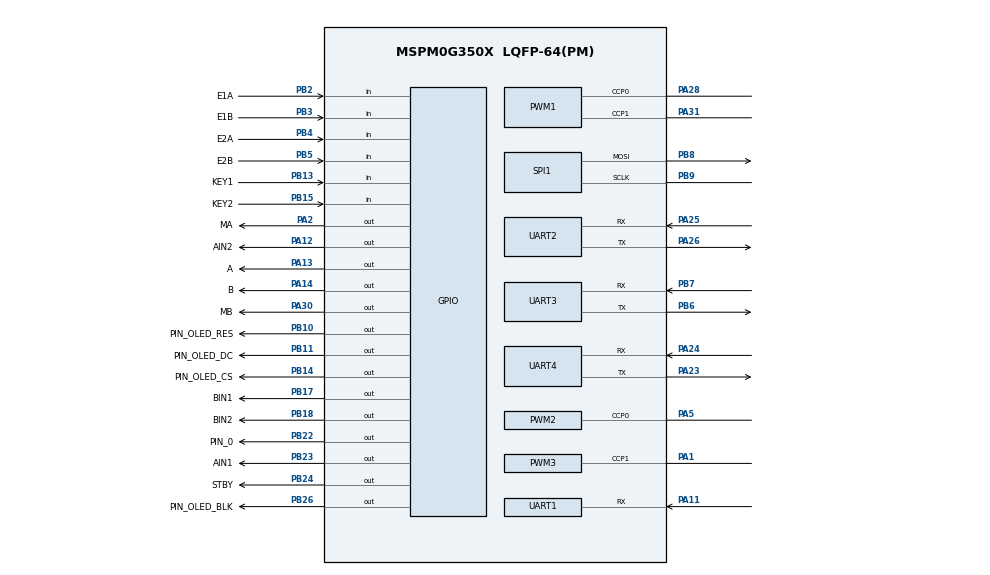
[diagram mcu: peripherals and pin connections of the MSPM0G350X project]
/**
 * @cliArgs --device "MSPM0G350X" --part "Default" --package "LQFP-64(PM)" --product "mspm0_sdk@2.10.00.04"
 * @versions {"tool":"1.26.2+4477"}
 */

/**
 * Import the modules used in this configuration.
 */
const GPIO   = scripting.addModule("/ti/driverlib/GPIO", {}, false);
const GPIO1  = GPIO.addInstance();
const GPIO2  = GPIO.addInstance();
const GPIO3  = GPIO.addInstance();
const GPIO4  = GPIO.addInstance();
const GPIO5  = GPIO.addInstance();
const GPIO6  = GPIO.addInstance();
const GPIO7  = GPIO.addInstance();
const GPIO8  = GPIO.addInstance();
const I2C    = scripting.addModule("/ti/driverlib/I2C", {}, false);
const I2C1   = I2C.addInstance();
const PWM    = scripting.addModule("/ti/driverlib/PWM", {}, false);
const PWM1   = PWM.addInstance();
const PWM2   = PWM.addInstance();
const PWM3   = PWM.addInstance();
const SPI    = scripting.addModule("/ti/driverlib/SPI", {}, false);
const SPI1   = SPI.addInstance();
const SYSCTL = scripting.addModule("/ti/driverlib/SYSCTL");
const TIMER  = scripting.addModule("/ti/driverlib/TIMER", {}, false);
const TIMER1 = TIMER.addInstance();
const UART   = scripting.addModule("/ti/driverlib/UART", {}, false);
const UART1  = UART.addInstance();
const UART2  = UART.addInstance();
const UART3  = UART.addInstance();
const UART4  = UART.addInstance();

/**
 * Write custom configuration values to the imported modules.
 */
const divider7       = system.clockTree["PLL_PDIV"];
divider7.divideValue = 2;

const divider9       = system.clockTree["UDIV"];
divider9.divideValue = 2;

const multiplier2         = system.clockTree["PLL_QDIV"];
multiplier2.multiplyValue = 5;

const mux8       = system.clockTree["HSCLKMUX"];
mux8.inputSelect = "HSCLKMUX_SYSPLL2X";

const pinFunction4       = system.clockTree["HFXT"];
pinFunction4.HFXTStartup = 10;

GPIO1.$name                         = "DC_MOTOR";
GPIO1.associatedPins.create(5);
GPIO1.associatedPins[0].$name       = "STBY";
GPIO1.associatedPins[0].pin.$assign = "PB24";
GPIO1.associatedPins[1].$name       = "AIN1";
GPIO1.associatedPins[1].pin.$assign = "PB23";
GPIO1.associatedPins[2].$name       = "AIN2";
GPIO1.associatedPins[2].pin.$assign = "PA12";
GPIO1.associatedPins[3].$name       = "BIN1";
GPIO1.associatedPins[3].pin.$assign = "PB17";
GPIO1.associatedPins[4].$name       = "BIN2";
GPIO1.associatedPins[4].pin.$assign = "PB18";

const Board = scripting.addModule("/ti/driverlib/Board", {}, false);

GPIO2.$name                         = "KEY";
GPIO2.associatedPins.create(2);
GPIO2.associatedPins[0].$name       = "KEY2";
GPIO2.associatedPins[0].direction   = "INPUT";
GPIO2.associatedPins[0].interruptEn = true;
GPIO2.associatedPins[0].polarity    = "RISE";
GPIO2.associatedPins[0].pin.$assign = "PB15";
GPIO2.associatedPins[1].$name       = "KEY1";
GPIO2.associatedPins[1].direction   = "INPUT";
GPIO2.associatedPins[1].interruptEn = true;
GPIO2.associatedPins[1].polarity    = "RISE";
GPIO2.associatedPins[1].pin.$assign = "PB13";

GPIO3.$name                               = "ENCODERA";
GPIO3.associatedPins.create(2);
GPIO3.associatedPins[0].$name             = "E1A";
GPIO3.associatedPins[0].direction         = "INPUT";
GPIO3.associatedPins[0].interruptEn       = true;
GPIO3.associatedPins[0].interruptPriority = "0";
GPIO3.associatedPins[0].polarity          = "RISE";
GPIO3.associatedPins[0].pin.$assign       = "PB2";
GPIO3.associatedPins[1].$name             = "E1B";
GPIO3.associatedPins[1].direction         = "INPUT";
GPIO3.associatedPins[1].interruptEn       = true;
GPIO3.associatedPins[1].interruptPriority = "0";
GPIO3.associatedPins[1].polarity          = "RISE";
GPIO3.associatedPins[1].pin.$assign       = "PB3";

GPIO4.$name                               = "ENCODERB";
GPIO4.associatedPins.create(2);
GPIO4.associatedPins[0].$name             = "E2A";
GPIO4.associatedPins[0].direction         = "INPUT";
GPIO4.associatedPins[0].interruptEn       = true;
GPIO4.associatedPins[0].interruptPriority = "0";
GPIO4.associatedPins[0].polarity          = "RISE";
GPIO4.associatedPins[0].pin.$assign       = "PB4";
GPIO4.associatedPins[1].$name             = "E2B";
GPIO4.associatedPins[1].direction         = "INPUT";
GPIO4.associatedPins[1].interruptEn       = true;
GPIO4.associatedPins[1].interruptPriority = "0";
GPIO4.associatedPins[1].polarity          = "RISE";
GPIO4.associatedPins[1].pin.$assign       = "PB5";

GPIO5.$name                              = "LED";
GPIO5.associatedPins[0].$name            = "PIN_0";
GPIO5.associatedPins[0].internalResistor = "PULL_DOWN";
GPIO5.associatedPins[0].pin.$assign      = "PB22";

GPIO6.$name                         = "DIR";
GPIO6.associatedPins.create(2);
GPIO6.associatedPins[0].$name       = "A";
GPIO6.associatedPins[0].pin.$assign = "PA13";
GPIO6.associatedPins[1].$name       = "B";
GPIO6.associatedPins[1].pin.$assign = "PA14";

GPIO7.$name                         = "GPIO_OLED";
GPIO7.associatedPins.create(4);
GPIO7.associatedPins[0].$name       = "PIN_OLED_RES";
GPIO7.associatedPins[0].pin.$assign = "PB10";
GPIO7.associatedPins[1].$name       = "PIN_OLED_DC";
GPIO7.associatedPins[1].pin.$assign = "PB11";
GPIO7.associatedPins[2].$name       = "PIN_OLED_CS";
GPIO7.associatedPins[2].pin.$assign = "PB14";
GPIO7.associatedPins[3].$name       = "PIN_OLED_BLK";
GPIO7.associatedPins[3].pin.$assign = "PB26";

GPIO8.$name                         = "EN";
GPIO8.associatedPins.create(2);
GPIO8.associatedPins[0].$name       = "MA";
GPIO8.associatedPins[0].pin.$assign = "PA2";
GPIO8.associatedPins[1].$name       = "MB";
GPIO8.associatedPins[1].pin.$assign = "PA30";

I2C1.$name                             = "I2C_OLED";
I2C1.basicEnableController             = true;
I2C1.basicControllerStandardBusSpeed   = "Fast";
I2C1.sdaPinConfig.hideOutputInversion  = scripting.forceWrite(false);
I2C1.sdaPinConfig.onlyInternalResistor = scripting.forceWrite(false);
I2C1.sdaPinConfig.passedPeripheralType = scripting.forceWrite("Digital");
I2C1.sdaPinConfig.$name                = "ti_driverlib_gpio_GPIOPinGeneric5";
I2C1.sclPinConfig.hideOutputInversion  = scripting.forceWrite(false);
I2C1.sclPinConfig.onlyInternalResistor = scripting.forceWrite(false);
I2C1.sclPinConfig.passedPeripheralType = scripting.forceWrite("Digital");
I2C1.sclPinConfig.$name                = "ti_driverlib_gpio_GPIOPinGeneric6";

PWM1.$name                              = "PWMAB";
PWM1.clockDivider                       = 2;
PWM1.timerStartTimer                    = true;
PWM1.clockPrescale                      = 20;
PWM1.pwmMode                            = "EDGE_ALIGN_UP";
PWM1.timerCount                         = 100;
PWM1.peripheral.$assign                 = "TIMA1";
PWM1.peripheral.ccp0Pin.$assign         = "PA28";
PWM1.peripheral.ccp1Pin.$assign         = "PA31";
PWM1.PWM_CHANNEL_0.$name                = "ti_driverlib_pwm_PWMTimerCC0";
PWM1.PWM_CHANNEL_1.$name                = "ti_driverlib_pwm_PWMTimerCC1";
PWM1.ccp0PinConfig.direction            = scripting.forceWrite("OUTPUT");
PWM1.ccp0PinConfig.hideOutputInversion  = scripting.forceWrite(false);
PWM1.ccp0PinConfig.onlyInternalResistor = scripting.forceWrite(false);
PWM1.ccp0PinConfig.passedPeripheralType = scripting.forceWrite("Digital");
PWM1.ccp0PinConfig.$name                = "ti_driverlib_gpio_GPIOPinGeneric0";
PWM1.ccp1PinConfig.direction            = scripting.forceWrite("OUTPUT");
PWM1.ccp1PinConfig.hideOutputInversion  = scripting.forceWrite(false);
PWM1.ccp1PinConfig.onlyInternalResistor = scripting.forceWrite(false);
PWM1.ccp1PinConfig.passedPeripheralType = scripting.forceWrite("Digital");
PWM1.ccp1PinConfig.$name                = "ti_driverlib_gpio_GPIOPinGeneric2";

PWM2.$name                              = "PWM_0";
PWM2.timerStartTimer                    = true;
PWM2.ccIndex                            = [0];
PWM2.pwmMode                            = "EDGE_ALIGN_UP";
PWM2.timerCount                         = 1;
PWM2.clockPrescale                      = 4;
PWM2.PWM_CHANNEL_0.$name                = "ti_driverlib_pwm_PWMTimerCC2";
PWM2.ccp0PinConfig.direction            = scripting.forceWrite("OUTPUT");
PWM2.ccp0PinConfig.hideOutputInversion  = scripting.forceWrite(false);
PWM2.ccp0PinConfig.onlyInternalResistor = scripting.forceWrite(false);
PWM2.ccp0PinConfig.passedPeripheralType = scripting.forceWrite("Digital");
PWM2.ccp0PinConfig.$name                = "ti_driverlib_gpio_GPIOPinGeneric13";
PWM2.peripheral.$assign                 = "TIMG0";
PWM2.peripheral.ccp0Pin.$assign         = "PA5";

PWM3.$name                              = "PWM_1";
PWM3.clockPrescale                      = 8;
PWM3.pwmMode                            = "EDGE_ALIGN_UP";
PWM3.ccIndex                            = [1];
PWM3.timerCount                         = 1;
PWM3.timerStartTimer                    = true;
PWM3.ccp1PinConfig.direction            = scripting.forceWrite("OUTPUT");
PWM3.ccp1PinConfig.hideOutputInversion  = scripting.forceWrite(false);
PWM3.ccp1PinConfig.onlyInternalResistor = scripting.forceWrite(false);
PWM3.ccp1PinConfig.passedPeripheralType = scripting.forceWrite("Digital");
PWM3.ccp1PinConfig.$name                = "ti_driverlib_gpio_GPIOPinGeneric16";
PWM3.peripheral.$assign                 = "TIMA0";
PWM3.peripheral.ccp1Pin.$assign         = "PA1";
PWM3.PWM_CHANNEL_1.$name                = "ti_driverlib_pwm_PWMTimerCC3";

SPI1.$name                              = "SPI_OLED";
SPI1.frameFormat                        = "MOTO3";
SPI1.direction                          = "PICO";
SPI1.sclkPinConfig.direction            = scripting.forceWrite("OUTPUT");
SPI1.sclkPinConfig.onlyInternalResistor = scripting.forceWrite(false);
SPI1.sclkPinConfig.passedPeripheralType = scripting.forceWrite("Digital");
SPI1.sclkPinConfig.$name                = "ti_driverlib_gpio_GPIOPinGeneric7";
SPI1.mosiPinConfig.direction            = scripting.forceWrite("OUTPUT");
SPI1.mosiPinConfig.hideOutputInversion  = scripting.forceWrite(false);
SPI1.mosiPinConfig.onlyInternalResistor = scripting.forceWrite(false);
SPI1.mosiPinConfig.passedPeripheralType = scripting.forceWrite("Digital");
SPI1.mosiPinConfig.$name                = "ti_driverlib_gpio_GPIOPinGeneric12";
SPI1.peripheral.$assign                 = "SPI1";
SPI1.peripheral.sclkPin.$assign         = "PB9";
SPI1.peripheral.mosiPin.$assign         = "PB8";

SYSCTL.forceDefaultClkConfig = true;
SYSCTL.clockTreeEn           = true;

TIMER1.$name              = "TIMER_0";
TIMER1.timerStartTimer    = true;
TIMER1.interrupts         = ["ZERO"];
TIMER1.timerMode          = "PERIODIC";
TIMER1.timerClkDiv        = 8;
TIMER1.timerClkPrescale   = 128;
TIMER1.timerPeriod        = "20 ms";
TIMER1.peripheral.$assign = "TIMG7";

UART1.$name                            = "UART_BNO08X";
UART1.targetBaudRate                   = 115200;
UART1.direction                        = "RX";
UART1.enableFIFO                       = true;
UART1.rxTimeoutValue                   = 1;
UART1.enabledInterrupts                = ["RX_TIMEOUT_ERROR"];
UART1.enabledDMARXTriggers             = "DL_UART_DMA_INTERRUPT_RX";
UART1.rxPinConfig.hideOutputInversion  = scripting.forceWrite(false);
UART1.rxPinConfig.onlyInternalResistor = scripting.forceWrite(false);
UART1.rxPinConfig.passedPeripheralType = scripting.forceWrite("Digital");
UART1.rxPinConfig.$name                = "ti_driverlib_gpio_GPIOPinGeneric1";
UART1.peripheral.$assign               = "UART0";
UART1.peripheral.rxPin.$assign         = "PA11";
UART1.DMA_CHANNEL_RX.addressMode       = "f2b";
UART1.DMA_CHANNEL_RX.srcLength         = "BYTE";
UART1.DMA_CHANNEL_RX.dstLength         = "BYTE";
UART1.DMA_CHANNEL_RX.$name             = "DMA_BNO08X";

UART2.$name                            = "UART_DEBUG";
UART2.targetBaudRate                   = 115200;
UART2.enabledInterrupts                = ["RX"];
UART2.peripheral.rxPin.$assign         = "PA25";
UART2.peripheral.txPin.$assign         = "PA26";
UART2.txPinConfig.direction            = scripting.forceWrite("OUTPUT");
UART2.txPinConfig.hideOutputInversion  = scripting.forceWrite(false);
UART2.txPinConfig.onlyInternalResistor = scripting.forceWrite(false);
UART2.txPinConfig.passedPeripheralType = scripting.forceWrite("Digital");
UART2.txPinConfig.$name                = "ti_driverlib_gpio_GPIOPinGeneric3";
UART2.rxPinConfig.hideOutputInversion  = scripting.forceWrite(false);
UART2.rxPinConfig.onlyInternalResistor = scripting.forceWrite(false);
UART2.rxPinConfig.passedPeripheralType = scripting.forceWrite("Digital");
UART2.rxPinConfig.$name                = "ti_driverlib_gpio_GPIOPinGeneric4";

UART3.$name                            = "UART_STEPMOTOR1";
UART3.targetBaudRate                   = 115200;
UART3.peripheral.rxPin.$assign         = "PB7";
UART3.peripheral.txPin.$assign         = "PB6";
UART3.txPinConfig.direction            = scripting.forceWrite("OUTPUT");
UART3.txPinConfig.hideOutputInversion  = scripting.forceWrite(false);
UART3.txPinConfig.onlyInternalResistor = scripting.forceWrite(false);
UART3.txPinConfig.passedPeripheralType = scripting.forceWrite("Digital");
UART3.txPinConfig.$name                = "ti_driverlib_gpio_GPIOPinGeneric8";
UART3.rxPinConfig.hideOutputInversion  = scripting.forceWrite(false);
UART3.rxPinConfig.onlyInternalResistor = scripting.forceWrite(false);
UART3.rxPinConfig.passedPeripheralType = scripting.forceWrite("Digital");
UART3.rxPinConfig.$name                = "ti_driverlib_gpio_GPIOPinGeneric9";

UART4.$name                            = "UART_STEPMOTOR2";
UART4.targetBaudRate                   = 115200;
UART4.peripheral.$assign               = "UART2";
UART4.peripheral.rxPin.$assign         = "PA24";
UART4.peripheral.txPin.$assign         = "PA23";
UART4.txPinConfig.direction            = scripting.forceWrite("OUTPUT");
UART4.txPinConfig.hideOutputInversion  = scripting.forceWrite(false);
UART4.txPinConfig.onlyInternalResistor = scripting.forceWrite(false);
UART4.txPinConfig.passedPeripheralType = scripting.forceWrite("Digital");
UART4.txPinConfig.$name                = "ti_driverlib_gpio_GPIOPinGeneric10";
UART4.rxPinConfig.hideOutputInversion  = scripting.forceWrite(false);
UART4.rxPinConfig.onlyInternalResistor = scripting.forceWrite(false);
UART4.rxPinConfig.passedPeripheralType = scripting.forceWrite("Digital");
UART4.rxPinConfig.$name                = "ti_driverlib_gpio_GPIOPinGeneric11";

/**
 * Pinmux solution for unlocked pins/peripherals. This ensures that minor changes to the automatic solver in a future
 * version of the tool will not impact the pinmux you originally saw.  These lines can be completely deleted in order to
 * re-solve from scratch.
 */
Board.peripheral.$suggestSolution                = "DEBUGSS";
Board.peripheral.swclkPin.$suggestSolution       = "PA20";
Board.peripheral.swdioPin.$suggestSolution       = "PA19";
I2C1.peripheral.$suggestSolution                 = "I2C1";
I2C1.peripheral.sdaPin.$suggestSolution          = "PA10";
I2C1.peripheral.sclPin.$suggestSolution          = "PA15";
UART1.DMA_CHANNEL_RX.peripheral.$suggestSolution = "DMA_CH0";
UART2.peripheral.$suggestSolution                = "UART3";
UART3.peripheral.$suggestSolution                = "UART1";
